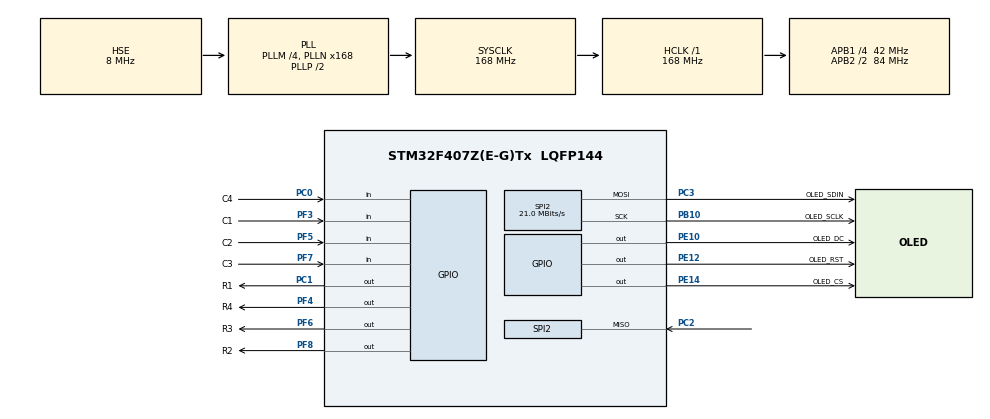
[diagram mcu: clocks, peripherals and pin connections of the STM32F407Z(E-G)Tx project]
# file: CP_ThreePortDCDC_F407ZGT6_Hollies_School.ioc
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Mcu.Family=STM32F4
Mcu.Name=STM32F407Z(E-G)Tx
Mcu.Package=LQFP144
NVIC.PriorityGroup=NVIC_PRIORITYGROUP_4
PA13.Mode=Serial_Wire
PA13.Signal=SYS_JTMS-SWDIO
PA14.Mode=Serial_Wire
PA14.Signal=SYS_JTCK-SWCLK
PB10.GPIO_Label=OLED_SCLK
PB10.Mode=Full_Duplex_Master
PB10.Signal=SPI2_SCK
PC0.GPIO_Label=C4
PC0.GPIO_PuPd=GPIO_PULLUP
PC0.Signal=GPIO_Input
PC1.GPIO_Label=R1
PC1.Signal=GPIO_Output
PC14-OSC32_IN.Mode=LSE-External-Oscillator
PC14-OSC32_IN.Signal=RCC_OSC32_IN
PC15-OSC32_OUT.Mode=LSE-External-Oscillator
PC15-OSC32_OUT.Signal=RCC_OSC32_OUT
PC2.Mode=Full_Duplex_Master
PC2.Signal=SPI2_MISO
PC3.GPIO_Label=OLED_SDIN
PC3.Mode=Full_Duplex_Master
PC3.Signal=SPI2_MOSI
PE10.GPIO_Label=OLED_DC
PE10.Signal=GPIO_Output
PE12.GPIO_Label=OLED_RST
PE12.Signal=GPIO_Output
PE14.GPIO_Label=OLED_CS
PE14.Signal=GPIO_Output
PF3.GPIO_Label=C1
PF3.GPIO_PuPd=GPIO_PULLUP
PF3.Signal=GPIO_Input
PF4.GPIO_Label=R4
PF4.Signal=GPIO_Output
PF5.GPIO_Label=C2
PF5.GPIO_PuPd=GPIO_PULLUP
PF5.Signal=GPIO_Input
PF6.GPIO_Label=R3
PF6.Signal=GPIO_Output
PF7.GPIO_Label=C3
PF7.GPIO_PuPd=GPIO_PULLUP
PF7.Signal=GPIO_Input
PF8.GPIO_Label=R2
PF8.Signal=GPIO_Output
PH0-OSC_IN.Mode=HSE-External-Oscillator
PH0-OSC_IN.Signal=RCC_OSC_IN
PH1-OSC_OUT.Mode=HSE-External-Oscillator
PH1-OSC_OUT.Signal=RCC_OSC_OUT
ProjectManager.HeapSize=0x200
ProjectManager.StackSize=0x400
ProjectManager.TargetToolchain=STM32CubeIDE
RCC.48MHZClocksFreq_Value=84000000
RCC.AHBFreq_Value=168000000
RCC.APB1CLKDivider=RCC_HCLK_DIV4
RCC.APB1Freq_Value=42000000
RCC.APB1TimFreq_Value=84000000
RCC.APB2CLKDivider=RCC_HCLK_DIV2
RCC.APB2Freq_Value=84000000
RCC.APB2TimFreq_Value=168000000
RCC.CortexFreq_Value=168000000
RCC.HCLKFreq_Value=168000000
RCC.HSE_VALUE=8000000
RCC.HSI_VALUE=16000000
RCC.PLLM=4
RCC.PLLN=168
RCC.PLLSourceVirtual=RCC_PLLSOURCE_HSE
RCC.SYSCLKFreq_VALUE=168000000
RCC.SYSCLKSource=RCC_SYSCLKSOURCE_PLLCLK
RCC.VCOOutputFreq_Value=336000000
SPI2.CalculateBaudRate=21.0 MBits/s
SPI2.Direction=SPI_DIRECTION_2LINES
SPI2.Mode=SPI_MODE_MASTER
SPI2.VirtualType=VM_MASTER
board=custom

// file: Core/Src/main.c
/* USER CODE BEGIN Header */
/**
  ******************************************************************************
  * @file           : main.c
  * @brief          : Main program body
  ******************************************************************************
  * @attention
  *
  * Copyright (c) 2023 STMicroelectronics.
  * All rights reserved.
  *
  * This software is licensed under terms that can be found in the LICENSE file
  * in the root directory of this software component.
  * If no LICENSE file comes with this software, it is provided AS-IS.
  *
  ******************************************************************************
  */
/* USER CODE END Header */
#include "main.h"

/* USER CODE BEGIN Includes */
#include "oled_spi.h"
/* USER CODE END Includes */

SPI_HandleTypeDef hspi2;

void SystemClock_Config(void);
static void MX_GPIO_Init(void);
static void MX_SPI2_Init(void);

int main(void)
{

  /* MCU Configuration--------------------------------------------------------*/

  /* Reset of all peripherals, Initializes the Flash interface and the Systick. */
  HAL_Init();

  /* USER CODE BEGIN Init */
  OLED_Init();	//oled
  /* USER CODE END Init */

  /* Configure the system clock */
  SystemClock_Config();

  /* Initialize all configured peripherals */
  MX_GPIO_Init();
  MX_SPI2_Init();
  /* USER CODE BEGIN 2 */
  OLED_Display_On();
  /* USER CODE END 2 */

  /* Infinite loop */
  while (1)
  {

    /* USER CODE BEGIN 3 */
	OLED_ShowString(0,0,"DC_VSIN:");

  }
  /* USER CODE END 3 */
}

void SystemClock_Config(void)
{
  RCC_OscInitTypeDef RCC_OscInitStruct = {0};
  RCC_ClkInitTypeDef RCC_ClkInitStruct = {0};

  /** Configure the main internal regulator output voltage
  */
  __HAL_RCC_PWR_CLK_ENABLE();
  __HAL_PWR_VOLTAGESCALING_CONFIG(PWR_REGULATOR_VOLTAGE_SCALE1);

  /** Initializes the RCC Oscillators according to the specified parameters
  * in the RCC_OscInitTypeDef structure.
  */
  RCC_OscInitStruct.OscillatorType = RCC_OSCILLATORTYPE_HSE;
  RCC_OscInitStruct.HSEState = RCC_HSE_ON;
  RCC_OscInitStruct.PLL.PLLState = RCC_PLL_ON;
  RCC_OscInitStruct.PLL.PLLSource = RCC_PLLSOURCE_HSE;
  RCC_OscInitStruct.PLL.PLLM = 4;
  RCC_OscInitStruct.PLL.PLLN = 168;
  RCC_OscInitStruct.PLL.PLLP = RCC_PLLP_DIV2;
  RCC_OscInitStruct.PLL.PLLQ = 4;
  if (HAL_RCC_OscConfig(&RCC_OscInitStruct) != HAL_OK)
  {
    Error_Handler();
  }

  /** Initializes the CPU, AHB and APB buses clocks
  */
  RCC_ClkInitStruct.ClockType = RCC_CLOCKTYPE_HCLK|RCC_CLOCKTYPE_SYSCLK
                              |RCC_CLOCKTYPE_PCLK1|RCC_CLOCKTYPE_PCLK2;
  RCC_ClkInitStruct.SYSCLKSource = RCC_SYSCLKSOURCE_PLLCLK;
  RCC_ClkInitStruct.AHBCLKDivider = RCC_SYSCLK_DIV1;
  RCC_ClkInitStruct.APB1CLKDivider = RCC_HCLK_DIV4;
  RCC_ClkInitStruct.APB2CLKDivider = RCC_HCLK_DIV2;

  if (HAL_RCC_ClockConfig(&RCC_ClkInitStruct, FLASH_LATENCY_5) != HAL_OK)
  {
    Error_Handler();
  }
}

static void MX_SPI2_Init(void)
{

  /* SPI2 parameter configuration*/
  hspi2.Instance = SPI2;
  hspi2.Init.Mode = SPI_MODE_MASTER;
  hspi2.Init.Direction = SPI_DIRECTION_2LINES;
  hspi2.Init.DataSize = SPI_DATASIZE_8BIT;
  hspi2.Init.CLKPolarity = SPI_POLARITY_LOW;
  hspi2.Init.CLKPhase = SPI_PHASE_1EDGE;
  hspi2.Init.NSS = SPI_NSS_SOFT;
  hspi2.Init.BaudRatePrescaler = SPI_BAUDRATEPRESCALER_2;
  hspi2.Init.FirstBit = SPI_FIRSTBIT_MSB;
  hspi2.Init.TIMode = SPI_TIMODE_DISABLE;
  hspi2.Init.CRCCalculation = SPI_CRCCALCULATION_DISABLE;
  hspi2.Init.CRCPolynomial = 10;
  if (HAL_SPI_Init(&hspi2) != HAL_OK)
  {
    Error_Handler();
  }

}

static void MX_GPIO_Init(void)
{
  GPIO_InitTypeDef GPIO_InitStruct = {0};

  /* GPIO Ports Clock Enable */
  __HAL_RCC_GPIOC_CLK_ENABLE();
  __HAL_RCC_GPIOF_CLK_ENABLE();
  __HAL_RCC_GPIOH_CLK_ENABLE();
  __HAL_RCC_GPIOE_CLK_ENABLE();
  __HAL_RCC_GPIOB_CLK_ENABLE();
  __HAL_RCC_GPIOA_CLK_ENABLE();

  /*Configure GPIO pin Output Level */
  HAL_GPIO_WritePin(GPIOF, R4_Pin|R3_Pin|R2_Pin, GPIO_PIN_RESET);

  /*Configure GPIO pin Output Level */
  HAL_GPIO_WritePin(R1_GPIO_Port, R1_Pin, GPIO_PIN_RESET);

  /*Configure GPIO pin Output Level */
  HAL_GPIO_WritePin(GPIOE, OLED_DC_Pin|OLED_RST_Pin|OLED_CS_Pin, GPIO_PIN_RESET);

  /*Configure GPIO pins : C1_Pin C2_Pin C3_Pin */
  GPIO_InitStruct.Pin = C1_Pin|C2_Pin|C3_Pin;
  GPIO_InitStruct.Mode = GPIO_MODE_INPUT;
  GPIO_InitStruct.Pull = GPIO_PULLUP;
  HAL_GPIO_Init(GPIOF, &GPIO_InitStruct);

  /*Configure GPIO pins : R4_Pin R3_Pin R2_Pin */
  GPIO_InitStruct.Pin = R4_Pin|R3_Pin|R2_Pin;
  GPIO_InitStruct.Mode = GPIO_MODE_OUTPUT_PP;
  GPIO_InitStruct.Pull = GPIO_NOPULL;
  GPIO_InitStruct.Speed = GPIO_SPEED_FREQ_LOW;
  HAL_GPIO_Init(GPIOF, &GPIO_InitStruct);

  /*Configure GPIO pin : C4_Pin */
  GPIO_InitStruct.Pin = C4_Pin;
  GPIO_InitStruct.Mode = GPIO_MODE_INPUT;
  GPIO_InitStruct.Pull = GPIO_PULLUP;
  HAL_GPIO_Init(C4_GPIO_Port, &GPIO_InitStruct);

  /*Configure GPIO pin : R1_Pin */
  GPIO_InitStruct.Pin = R1_Pin;
  GPIO_InitStruct.Mode = GPIO_MODE_OUTPUT_PP;
  GPIO_InitStruct.Pull = GPIO_NOPULL;
  GPIO_InitStruct.Speed = GPIO_SPEED_FREQ_LOW;
  HAL_GPIO_Init(R1_GPIO_Port, &GPIO_InitStruct);

  /*Configure GPIO pins : OLED_DC_Pin OLED_RST_Pin OLED_CS_Pin */
  GPIO_InitStruct.Pin = OLED_DC_Pin|OLED_RST_Pin|OLED_CS_Pin;
  GPIO_InitStruct.Mode = GPIO_MODE_OUTPUT_PP;
  GPIO_InitStruct.Pull = GPIO_NOPULL;
  GPIO_InitStruct.Speed = GPIO_SPEED_FREQ_LOW;
  HAL_GPIO_Init(GPIOE, &GPIO_InitStruct);

}

void Error_Handler(void)
{
  __disable_irq();
  while (1)
  {
  }
}
